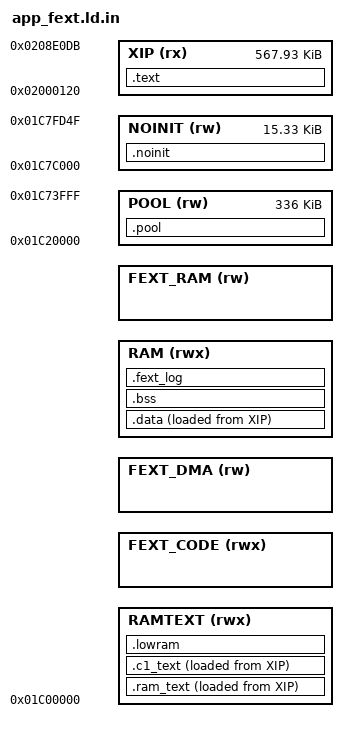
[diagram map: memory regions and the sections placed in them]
/* SPDX-License-Identifier: GPL-3.0-only
 * Copyright (C) 2026 Leo Kuroshita (@kurogedelic), Hügelton Instruments
 * (the fext build's windows: Copyright (C) 2026 Jacek Mariański) */
/* SLOOP's memory map with an fext module's RAM windows kept free (tools/build.py --fext, FELUCCA_FEXT=1).
 * app.ld's, with three holes; build.py writes build/fext/app_fext.ld from this file, the @...@ numbers being the
 * windows of firmware/src/fext_host.h (FEXT_CODE_*, FEXT_DMA_*, FEXT_RAM_*), and checks they lie where this layout
 * expects:
 *   RAMTEXT 0x01C00000..@RT_LO@     .ram_text, .c1_text, .lowram as app.ld (less room: the rt window takes the top)
 *   FEXT_CODE @RT_LO@..@RT_HI@      the module's code in RAM (its interrupts)
 *   FEXT_DMA @LOW_LO@..@LOW_HI@     the module's .data / .bss (a radio's DMA reaches it): the bottom of app.ld's RAM
 *   RAM     @LOW_HI@..@ANY_LO@      SLOOP's .data, .bss, then .fext_log (fext_host.c's log lines: not zeroed at
 *                                   boot, so the log of the run before a crash can be read)
 *   FEXT_RAM @ANY_LO@..@ANY_HI@     the module's .pool (its tasks' stacks): the top of app.ld's RAM region
 * The pool, the stacks and .noinit are app.ld's. _fext_* give fext_host.c the windows as linked (it refuses to load
 * a module when they are not fext_host.h's). */
MEMORY
{
    XIP      (rx)  : ORIGIN = 0x02000120, LENGTH = 0x8DFBC
    RAMTEXT  (rwx) : ORIGIN = 0x01C00000, LENGTH = @RAMTEXT_LEN@
    FEXT_CODE (rwx) : ORIGIN = @RT_LO@, LENGTH = @RT_LEN@
    FEXT_DMA (rw)  : ORIGIN = @LOW_LO@, LENGTH = @LOW_LEN@
    RAM      (rwx) : ORIGIN = @LOW_HI@, LENGTH = @RAM_LEN@
    FEXT_RAM (rw)  : ORIGIN = @ANY_LO@, LENGTH = @ANY_LEN@
    POOL     (rw)  : ORIGIN = 0x01C20000, LENGTH = 0x54000
    NOINIT   (rw)  : ORIGIN = 0x01C7C000, LENGTH = 0x3D50
}
SECTIONS
{
    .text : { KEEP(*(.text.crt0)) *(.text*) *(.rodata*) . = ALIGN(4); _etext = .; } > XIP
    .ram_text : { _rt_start = .; KEEP(*(.ram_text*)) . = ALIGN(4); } > RAMTEXT AT > XIP
    _rt_load = LOADADDR(.ram_text);
    .c1_text : { _c1_start = .; KEEP(*(.c1_text*)) . = ALIGN(4); _c1_end = .; } > RAMTEXT AT > XIP
    _c1_load = LOADADDR(.c1_text);
    _rt_end = _c1_end;
    .lowram (NOLOAD) : { . = ALIGN(8); _lr_start = .; *(.bss.c1stack) *(.lowram*) . = ALIGN(4); _lr_end = .; } > RAMTEXT
    .data : { . = ALIGN(4); _data_start = .; *(.data*) *(.sdata*) . = ALIGN(4); _data_end = .; } > RAM AT > XIP
    _data_load = LOADADDR(.data);
    .bss (NOLOAD) : { _bss_start = .; *(.bss*) *(.sbss*) *(COMMON) . = ALIGN(4); _bss_end = .; } > RAM
    .fext_log (NOLOAD) : { . = ALIGN(4); *(.fext_log*) . = ALIGN(4); _ram_used_end = .; } > RAM
    .pool (NOLOAD) : { _pool_start = .; *(.pool*) . = ALIGN(4); _pool_end = .; } > POOL
    .noinit (NOLOAD) : { *(.noinit) *(.noinit.*) } > NOINIT
    _guard0 = 0x01C74000; _ustack_lo = 0x01C74100; _ustack_top = 0x01C7A000;
    _guard1 = 0x01C7A000; _sstack_lo = 0x01C7A100; _sstack_top = 0x01C7C000;
    _fext_code_lo = ORIGIN(FEXT_CODE); _fext_code_hi = ORIGIN(FEXT_CODE) + LENGTH(FEXT_CODE);
    _fext_dma_lo = ORIGIN(FEXT_DMA); _fext_dma_hi = ORIGIN(FEXT_DMA) + LENGTH(FEXT_DMA);
    _fext_ram_lo = ORIGIN(FEXT_RAM); _fext_ram_hi = ORIGIN(FEXT_RAM) + LENGTH(FEXT_RAM);
    _ram_lo = ORIGIN(RAM); _ram_hi = ORIGIN(RAM) + LENGTH(RAM);
    /DISCARD/ : { *(.comment) *(.note*) }
}
